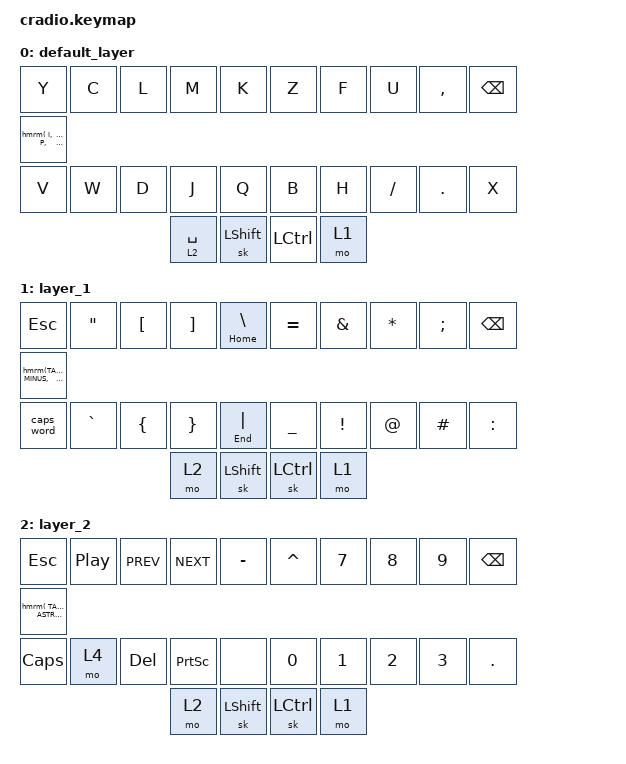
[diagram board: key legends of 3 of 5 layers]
// Copyright (c) 2022 The ZMK Contributors
// SPDX-License-Identifier: MIT

#include <behaviors.dtsi>
#include <dt-bindings/zmk/keys.h>
#include <dt-bindings/zmk/bt.h>

// Home row mods macro
#define MEH (LA(LC(LSFT)))
#
# define hmrm(a, b, c, d, e, f, g, h, i, j) &hmr LSHFT a &hmr LCTRL b &hmr LALT c &hmr LGUI d &kp e &kp f &hmr RGUI g &hmr RALT h &hmr RCTRL i &hmr RSHFT j

# define BSLHHOME &qt HOME BSLH   
# define PIPEEND &qt END PIPE
# define CA(x) &kp LC(LA(x))

/ {
    behaviors {
        qt: quick-tap {
            compatible = "zmk,behavior-hold-tap";
            #binding-cells = <2>;
            flavor = "tap-preferred";
            tapping-term-ms = <300>;
            quick-tap-ms = <175>;
            label = "QUICK_TAP";
            bindings = <&kp>, <&kp>;
        };
        qlt: quick-layer-tap {
            compatible = "zmk,behavior-hold-tap";
            #binding-cells = <2>;
            flavor = "tap-preferred";
            tapping-term-ms = <200>;
            quick-tap-ms = <175>;
            label = "QUICK_LAYER_TAP";
            bindings = <&mo>, <&kp>;
        };
        hmr: home-row-mods {
            compatible = "zmk,behavior-hold-tap";
            #binding-cells = <2>;
            flavor = "tap-preferred";
            tapping-term-ms = <300>;
            quick-tap-ms = <175>;
            label = "HOME_ROW_MODS";
            bindings = <&kp>, <&kp>;
        };
        sk {
            quick-release;
        };
        lts: layer-tap-switch {
                compatible = "zmk,behavior-hold-tap";
                #binding-cells = <2>;
                flavor = "tap-preferred";
                tapping-term-ms = <200>;
                quick-tap-ms = <175>;
                label = "LAYER_TAP_SWITCH";
                bindings = <&mo>, <&to>;
        };
    };
    conditional_layers {
        compatible = "zmk,conditional-layers";
        tri_layer {
            if-layers = <1 2>;
            then-layer = <3>;
        };
    };

    keymap {
        compatible = "zmk,keymap";
        default_layer {
            bindings = <
        //╭──────────┬──────────┬──────────┬──────────┬──────────╮   ╭──────────┬──────────┬──────────┬──────────┬──────────╮
        //│  Y       │  C       │  L       │  M       │  K       │   │  Z       │  F       │  U       │  , <     │  BCKSPC  │
            &kp Y      &kp C      &kp L      &kp M      &kp K          &kp Z      &kp F      &kp U      &kp COMMA   &kp BSPC
        //├──────────┼──────────┼──────────┼──────────┼──────────┤   ├──────────┼──────────┼──────────┼──────────┼──────────┤
        //│  I       │  S       │  R       │  T       │  G       │   │  P       │  N       │  E       │  A       │  O       │
       hmrm( I,         S,         R,         T,         G,             P,         N,         E,         A,         O)
        //├──────────┼──────────┼──────────┼──────────┼──────────┤   ├──────────┼──────────┼──────────┼──────────┼──────────┤
        //│  V       │  W       │  D       │  J       │  Q       │   │  B       │  H       │ / ?      │  . >     │  X       │
            &kp V      &kp W      &kp D      &kp J      &kp Q          &kp B      &kp H      &kp FSLH   &kp DOT    &kp X
        //╰──────────┴──────────┴──────────┼──────────┼──────────┤   ├──────────┼──────────┼──────────┴──────────┴──────────╯
                                          &qlt 2 SPACE  &sk LSHFT      &kp LCTRL  &mo 1
        //                                 ╰──────────┴──────────╯   ╰──────────┴──────────╯
            >;
        };

        layer_1 {
            bindings = <
        //╭──────────┬──────────┬──────────┬──────────┬──────────╮   ╭──────────┬──────────┬──────────┬──────────┬──────────╮
        //│ ESC      │  "       │ [        │  ]       │ '\'/HOME │   │ =        │ &        │ *        │ ;        │  BCKSPC  │
            &kp ESC    &kp DQT    &kp LBKT   &kp RBKT   BSLHHOME       &kp EQUAL  &kp AMPS   &kp ASTRK  &kp SEMI   &kp BSPC
        //├──────────┼──────────┼──────────┼──────────┼──────────┤   ├──────────┼──────────┼──────────┼──────────┼──────────┤
        //│ TAB      │  '       │  (       │  )       │ +        │   │ -        │ $        │ %        │ ^        │  ENTER   │
        hmrm(TAB,        SQT,       LPAR,     RPAR,     PLUS,      MINUS,     DOLLAR,    PERCENT,     CARET,        ENTER)
        //├──────────┼──────────┼──────────┼──────────┼──────────┤   ├──────────┼──────────┼──────────┼──────────┼──────────┤
        //│ CAPS     │  `       │  {       │  }       │ '|'/END  │   │ _        │ !        │ @        │ \#       │  :       │
           &caps_word  &kp GRAVE  &kp LBRC   &kp RBRC   PIPEEND        &kp UNDER  &kp EXCL  &kp AT      &kp HASH   &kp COLON
        //╰──────────┴──────────┴──────────┼──────────┼──────────┤   ├──────────┼──────────┼──────────┴──────────┴──────────╯
                                             &mo 2        &sk LSHFT   &sk LCTRL  &mo 1
        //                                 ╰──────────┴──────────╯   ╰──────────┴──────────╯
            >;
        };


        layer_2 {
            bindings = <
        //╭──────────┬──────────┬──────────┬──────────┬──────────╮   ╭──────────┬──────────┬──────────┬──────────┬──────────╮
        //│  ESC     │play/pause│  <<      │  >>      │  -       │   │  ^       │  7       │  8       │  9       │  BCKSPC  │
            &kp ESC    &kp C_PP  &kp C_PREV &kp C_NEXT  &kp MINUS      &kp CARET  &kp N7     &kp N8     &kp N9     &kp BSPC
        //├──────────┼──────────┼──────────┼──────────┼──────────┤   ├──────────┼──────────┼──────────┼──────────┼──────────┤
        //│  TAB     │  . (KP)  │  VOLDWN  │  VOLUP   │  +       │   │  *       │  4       │  5       │  6       │  ENTER   │
        hmrm( TAB,       DOT,       C_VOL_DN,  C_VOL_UP,  PLUS,          ASTRK,     N4,        N5,        N6,        ENTER)
        //├──────────┼──────────┼──────────┼──────────┼──────────┤   ├──────────┼──────────┼──────────┼──────────┼──────────┤
        //│ CAPS     │          │          │  PRSC    │          │   │  0       │  1       │  2       │  3       │  .       │
            &kp CAPS   &mo 4      &kp DEL    &kp PSCRN   &none         &kp N0     &kp N1     &kp N2     &kp N3     &kp DOT
        //╰──────────┴──────────┴──────────┼──────────┼──────────┤   ├──────────┼──────────┼──────────┴──────────┴──────────╯
                                             &mo 2      &sk LSHFT      &sk LCTRL  &mo 1
        //                                 ╰──────────┴──────────╯   ╰──────────┴──────────╯
            >;
        };


        // layer 3 for conditional layer switching
        layer_3 {
            bindings = <
        //╭──────────┬──────────┬──────────┬──────────┬──────────╮   ╭──────────┬──────────┬──────────┬──────────┬──────────╮
        //│ ESC      │   Q      │   UP     │          │PROFILE 0 │   │          │          │          │          │  BCKSPC  │
           &kp ESC      &kp Q      &kp UP     &trans    &bt BT_SEL 0   CA(H)      CA(J)      CA(K)      CA(L)      &kp BSPC
        //├──────────┼──────────┼──────────┼──────────┼──────────┤   ├──────────┼──────────┼──────────┼──────────┼──────────┤
        //│ TAB      │   LEFT   │   DOWN   │   RIGHT  │PROFILE 1 │   │  H       │  J       │  K       │  L       │  ENTER   │
          &kp TAB       &kp LEFT   &kp DOWN   &kp RIGHT &bt BT_SEL 1   &kp H      &kp J      &kp K      &kp L      &kp ENTER
        //├──────────┼──────────┼──────────┼──────────┼──────────┤   ├──────────┼──────────┼──────────┼──────────┼──────────┤
        //│          │          │          │ CLEAR BT │PROFILE 2 │   │          │          │          │          │          │
            &trans     CA(A)       &trans    &bt BT_CLR &bt BT_SEL 2   &trans     CA(SEMI)   CA(U)      CA(I)      &none
        //╰──────────┴──────────┴──────────┼──────────┼──────────┤   ├──────────┼──────────┼──────────┴──────────┴──────────╯
                                             &to 0      &sk LSHFT      &sk LCTRL     &none
        //                                 ╰──────────┴──────────╯   ╰──────────┴──────────╯
            >;
        };
        
        layer_4 {
            bindings = <
        //╭──────────┬──────────┬──────────┬──────────┬──────────╮   ╭──────────┬──────────┬──────────┬──────────┬──────────╮
        //│ RESET    │          │          │          │PROFILE 0 │   │          │          │          │          │  RESET   │
           &sys_reset  &trans     &trans     &trans    &bt BT_SEL 0    &kp F12    &kp F7     &kp F8     &kp F9    &sys_reset
        //├──────────┼──────────┼──────────┼──────────┼──────────┤   ├──────────┼──────────┼──────────┼──────────┼──────────┤
        //│BOOTLOADER│          │          │          │PROFILE 1 │   │          │          │          │          │BOOTLOADER│
          &bootloader  &trans     &trans     &trans    &bt BT_SEL 1    &kp F11    &kp F4     &kp F5     &kp F6   &bootloader
        //├──────────┼──────────┼──────────┼──────────┼──────────┤   ├──────────┼──────────┼──────────┼──────────┼──────────┤
        //│          │          │          │ CLEAR BT │PROFILE 2 │   │          │          │          │          │          │
            &trans     &mo 4      &trans    &bt BT_CLR &bt BT_SEL 2    &kp F10    &kp F1     &kp F2     &kp F3     &none
        //╰──────────┴──────────┴──────────┼──────────┼──────────┤   ├──────────┼──────────┼──────────┴──────────┴──────────╯
                                             &mo 2      &trans         &trans     &none
        //                                 ╰──────────┴──────────╯   ╰──────────┴──────────╯
            >;
        };
    };
};
